AUTOSAR XML (schema 4-2-1)
package /RootP_ASWC_A7D3
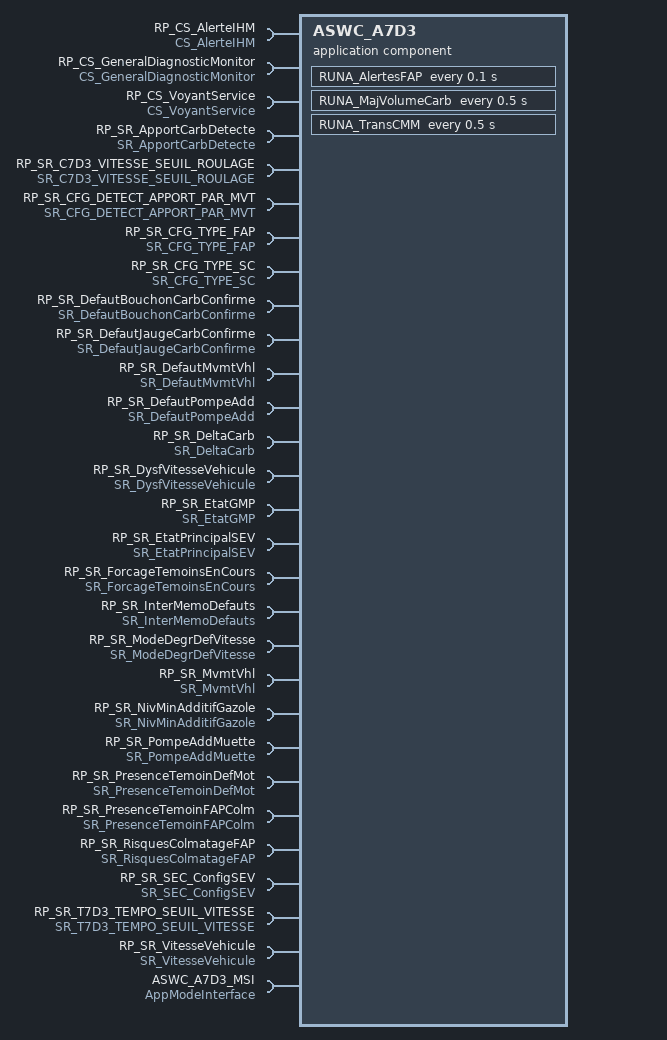
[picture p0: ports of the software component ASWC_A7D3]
  application sw component type ASWC_A7D3
    11 x provide/require port:
      PRP_SR_ContexteDefCalcAdditif: nonqueued-receiver-com-spec{data-element=ContexteDefCalcAdditif, enable-update=0, handle-data-status=1, handle-never-received=0, init-value=CONST_tLOG_0:0}, provided-required-interface=SR_ContexteDefCalcAdditif
      PRP_SR_ContexteDefCapteurBouchon: nonqueued-receiver-com-spec{data-element=ContexteDefCapteurBouchon, enable-update=0, handle-data-status=1, handle-never-received=0, init-value=CONST_tLOG_0:0}, provided-required-interface=SR_ContexteDefCapteurBouchon
      PRP_SR_ContexteDefInjecteur: nonqueued-receiver-com-spec{data-element=ContexteDefInjecteur, enable-update=0, handle-data-status=1, handle-never-received=0, init-value=CONST_tLOG_0:0}, provided-required-interface=SR_ContexteDefInjecteur
      PRP_SR_ContexteDefJaugeAdditif: nonqueued-receiver-com-spec{data-element=ContexteDefJaugeAdditif, enable-update=0, handle-data-status=1, handle-never-received=0, init-value=CONST_tLOG_0:0}, provided-required-interface=SR_ContexteDefJaugeAdditif
      PRP_SR_ContexteDefJaugeCarb: nonqueued-receiver-com-spec{data-element=ContexteDefJaugeCarb, enable-update=0, handle-data-status=1, handle-never-received=0, init-value=CONST_tLOG_0:0}, provided-required-interface=SR_ContexteDefJaugeCarb
      PRP_SR_ContexteDefPompe: nonqueued-receiver-com-spec{data-element=ContexteDefPompe, enable-update=0, handle-data-status=1, handle-never-received=0, init-value=CONST_tLOG_0:0}, provided-required-interface=SR_ContexteDefPompe
      PRP_SR_ContexteDefSondeTemp: nonqueued-receiver-com-spec{data-element=ContexteDefSondeTemp, enable-update=0, handle-data-status=1, handle-never-received=0, init-value=CONST_tLOG_0:0}, provided-required-interface=SR_ContexteDefSondeTemp
      PRP_SR_ContexteEtatAdditivation: nonqueued-receiver-com-spec{data-element=ContexteEtatAdditivation, enable-update=0, handle-data-status=1, handle-never-received=0, init-value=CONST_tLOG_1:1}, provided-required-interface=SR_ContexteEtatAdditivation
      PRP_SR_SAV_CompteurEnvoiDeltaCarb: nonqueued-receiver-com-spec{data-element=SAV_CompteurEnvoiDeltaCarb, enable-update=0, handle-data-status=1, handle-never-received=0, init-value=CONST_tBYTE_0:0}, provided-required-interface=SR_SAV_CompteurEnvoiDeltaCarb
      PRP_SR_SAV_VolCarbAjoute: nonqueued-receiver-com-spec{data-element=SAV_VolCarbAjoute, enable-update=0, handle-data-status=1, handle-never-received=0, init-value=CONST_tBYTE_0xFE:254}, provided-required-interface=SR_SAV_VolCarbAjoute
      PRP_SR_VoyRisqueColmatageFAP: nonqueued-receiver-com-spec{data-element=VoyRisqueColmatageFAP, enable-update=0, handle-data-status=1, handle-never-received=0, init-value=CONST_tLOG_0:0}, provided-required-interface=SR_VoyRisqueColmatageFAP
    29 x require port:
      RP_CS_AlerteIHM: required-interface=CS_AlerteIHM
      RP_CS_GeneralDiagnosticMonitor: required-interface=CS_GeneralDiagnosticMonitor
      RP_CS_VoyantService: required-interface=CS_VoyantService
      RP_SR_ApportCarbDetecte: nonqueued-receiver-com-spec{data-element=ApportCarbDetecte, enable-update=0, handle-data-status=1, handle-never-received=0, init-value=CONST_tLOG_0:0}, required-interface=SR_ApportCarbDetecte
      RP_SR_C7D3_VITESSE_SEUIL_ROULAGE: nonqueued-receiver-com-spec{data-element=C7D3_VITESSE_SEUIL_ROULAGE, enable-update=0, handle-data-status=1, handle-never-received=0, init-value=CONST_tBYTE_3:3}, required-interface=SR_C7D3_VITESSE_SEUIL_ROULAGE
      RP_SR_CFG_DETECT_APPORT_PAR_MVT: nonqueued-receiver-com-spec{data-element=CFG_DETECT_APPORT_PAR_MVT, enable-update=0, handle-data-status=1, handle-never-received=0, init-value=CONST_tLOG_0:0}, required-interface=SR_CFG_DETECT_APPORT_PAR_MVT
      RP_SR_CFG_TYPE_FAP: nonqueued-receiver-com-spec{data-element=CFG_TYPE_FAP, enable-update=0, handle-data-status=1, handle-never-received=0, init-value=CONST_t_cFAP_0:0}, required-interface=SR_CFG_TYPE_FAP
      RP_SR_CFG_TYPE_SC: nonqueued-receiver-com-spec{data-element=CFG_TYPE_SC, enable-update=0, handle-data-status=1, handle-never-received=0, init-value=CONST_CFG_TYPE_SC_t_cTypeSC_Euro_cTypeSC_Euro6:2}, required-interface=SR_CFG_TYPE_SC
      RP_SR_DefautBouchonCarbConfirme: nonqueued-receiver-com-spec{data-element=DefautBouchonCarbConfirme, enable-update=0, handle-data-status=1, handle-never-received=0, init-value=CONST_tLOG_0:0}, required-interface=SR_DefautBouchonCarbConfirme
      RP_SR_DefautJaugeCarbConfirme: nonqueued-receiver-com-spec{data-element=DefautJaugeCarbConfirme, enable-update=0, handle-data-status=1, handle-never-received=0, init-value=CONST_DefautJaugeCarbConfirme_t_cSDF_Defaut_cSDF_DefautAbsent:105}, required-interface=SR_DefautJaugeCarbConfirme
      RP_SR_DefautMvmtVhl: nonqueued-receiver-com-spec{data-element=DefautMvmtVhl, enable-update=0, handle-data-status=1, handle-never-received=0, init-value=CONST_tLOG_0:0}, required-interface=SR_DefautMvmtVhl
      RP_SR_DefautPompeAdd: nonqueued-receiver-com-spec{data-element=DefautPompeAdd, enable-update=0, handle-data-status=1, handle-never-received=0, init-value=CONST_tLOG_0:0}, required-interface=SR_DefautPompeAdd
      RP_SR_DeltaCarb: nonqueued-receiver-com-spec{data-element=DeltaCarb, enable-update=0, handle-data-status=1, handle-never-received=0, init-value=CONST_tWORD_0:0}, required-interface=SR_DeltaCarb
      RP_SR_DysfVitesseVehicule: nonqueued-receiver-com-spec{data-element=DysfVitesseVehicule, enable-update=0, handle-data-status=1, handle-never-received=0, init-value=CONST_t_cVitv_0:0}, required-interface=SR_DysfVitesseVehicule
      RP_SR_EtatGMP: nonqueued-receiver-com-spec{data-element=EtatGMP, enable-update=0, handle-data-status=1, handle-never-received=0, init-value=CONST_EtatGMP_t_GM_GMP_GM_GMPCoupe:1}, required-interface=SR_EtatGMP
      RP_SR_EtatPrincipalSEV: nonqueued-receiver-com-spec{data-element=EtatPrincipalSEV, enable-update=0, handle-data-status=1, handle-never-received=0, init-value=CONST_EtatPrincipalSEV_t_SEV_SEV_Arret:105}, required-interface=SR_EtatPrincipalSEV
      RP_SR_ForcageTemoinsEnCours: nonqueued-receiver-com-spec{data-element=ForcageTemoinsEnCours, enable-update=0, handle-data-status=1, handle-never-received=0, init-value=CONST_tLOG_0:0}, required-interface=SR_ForcageTemoinsEnCours
      RP_SR_InterMemoDefauts: nonqueued-receiver-com-spec{data-element=InterMemoDefauts, enable-update=0, handle-data-status=1, handle-never-received=0, init-value=CONST_tLOG_0:0}, required-interface=SR_InterMemoDefauts
      RP_SR_ModeDegrDefVitesse: nonqueued-receiver-com-spec{data-element=ModeDegrDefVitesse, enable-update=0, handle-data-status=1, handle-never-received=0, init-value=CONST_tLOG_0:0}, required-interface=SR_ModeDegrDefVitesse
      RP_SR_MvmtVhl: nonqueued-receiver-com-spec{data-element=MvmtVhl, enable-update=0, handle-data-status=1, handle-never-received=0, init-value=CONST_tLOG_0:0}, required-interface=SR_MvmtVhl
      RP_SR_NivMinAdditifGazole: nonqueued-receiver-com-spec{data-element=NivMinAdditifGazole, enable-update=0, handle-data-status=1, handle-never-received=0, init-value=CONST_tLOG_0:0}, required-interface=SR_NivMinAdditifGazole
      RP_SR_PompeAddMuette: nonqueued-receiver-com-spec{data-element=PompeAddMuette, enable-update=0, handle-data-status=1, handle-never-received=0, init-value=CONST_tLOG_0:0}, required-interface=SR_PompeAddMuette
      RP_SR_PresenceTemoinDefMot: nonqueued-receiver-com-spec{data-element=PresenceTemoinDefMot, enable-update=0, handle-data-status=1, handle-never-received=0, init-value=CONST_tLOG_0:0}, required-interface=SR_PresenceTemoinDefMot
      RP_SR_PresenceTemoinFAPColm: nonqueued-receiver-com-spec{data-element=PresenceTemoinFAPColm, enable-update=0, handle-data-status=1, handle-never-received=0, init-value=CONST_tLOG_0:0}, required-interface=SR_PresenceTemoinFAPColm
      RP_SR_RisquesColmatageFAP: nonqueued-receiver-com-spec{data-element=RisquesColmatageFAP, enable-update=0, handle-data-status=1, handle-never-received=0, init-value=CONST_tLOG_0:0}, required-interface=SR_RisquesColmatageFAP
      RP_SR_SEC_ConfigSEV: nonqueued-receiver-com-spec{data-element=SEC_ConfigSEV, enable-update=0, handle-data-status=1, handle-never-received=0, init-value=CONST_t_cCSEV_4:4}, required-interface=SR_SEC_ConfigSEV
      RP_SR_T7D3_TEMPO_SEUIL_VITESSE: nonqueued-receiver-com-spec{data-element=T7D3_TEMPO_SEUIL_VITESSE, enable-update=0, handle-data-status=1, handle-never-received=0, init-value=CONST_tBYTE_5:5}, required-interface=SR_T7D3_TEMPO_SEUIL_VITESSE
      RP_SR_VitesseVehicule: nonqueued-receiver-com-spec{data-element=VitesseVehicule, enable-update=0, handle-data-status=1, handle-never-received=0, init-value=CONST_tWORD_0:0}, required-interface=SR_VitesseVehicule
      ASWC_A7D3_MSI: required-interface=AppModeInterface
    behavior IB_ASWC_A7D3: data-type-mapping=ApplicationModeMapping, handle-termination-and-restart=NO-SUPPORT
      ar-typed-per-instance-memorys:
        17 x data:
          PA7D3_AlerteEnCoursDefautNivMiniAddGo: type=tLOG, init-value=CONST_tLOG_0:0
          PA7D3_AlerteEnCoursRisquesColmatageFAP: type=tLOG, init-value=CONST_tLOG_0:0
          PA7D3_ApportCarbDetectePrec: type=tLOG, init-value=CONST_tLOG_0:0
          PA7D3_CptTempoAppa_DefautPompeADD: type=tWORD, init-value=CONST_tWORD_0:0
          PA7D3_CptTempoDisp_DefautPompeADD: type=tWORD, init-value=CONST_tWORD_0:0
          PA7D3_DefautMvmtVhlPrec: type=tLOG, init-value=CONST_tLOG_0:0
          PA7D3_DefautPrec_DefautPompeADD: type=tBYTE, init-value=CONST_tBYTE_0:0
          PA7D3_FiltreF3: type=tWORD, init-value=CONST_tWORD_0:0
          PA7D3_FiltreGMP: type=tBYTE, init-value=CONST_tBYTE_0:0
          PA7D3_ModeDegrDefVitessePrec: type=tLOG, init-value=CONST_tLOG_0:0
          PA7D3_NivMinAdditifGazoleFiltre: type=tLOG, init-value=CONST_tLOG_0:0
          PA7D3_OldStateDef2_DefautPompeADD: type=tBYTE, init-value=CONST_tBYTE_0:0
          PA7D3_SAV_FrontApportCarbDetecte: type=tLOG, init-value=CONST_tLOG_0:0
          PA7D3_SAV_PremierPassageRealise: type=tLOG, init-value=CONST_tLOG_0:0
          PA7D3_TempoGMPNonTournant: type=tBYTE, init-value=CONST_tBYTE_0:0
          PA7D3_TempoMouvement: type=tBYTE, init-value=CONST_tBYTE_0:0
          PA7D3_TempoVitesse: type=tBYTE, init-value=CONST_tBYTE_0:0
      timing event RUNA_AlertesFAP_Cyclic: start-on-event=RUNA_AlertesFAP, period=0.1
        disabled-mode:
          ASWC_A7D3_MSI.AppMode.APP_WAKEUP
          ASWC_A7D3_MSI.AppMode.APP_OFF
          ASWC_A7D3_MSI.AppMode.APP_SYNC_INIT
          ASWC_A7D3_MSI.AppMode.APP_CONFIG
      timing event RUNA_MajVolumeCarb_Cyclic: start-on-event=RUNA_MajVolumeCarb, period=0.5
        disabled-mode:
          ASWC_A7D3_MSI.AppMode.APP_WAKEUP
          ASWC_A7D3_MSI.AppMode.APP_OFF
          ASWC_A7D3_MSI.AppMode.APP_SYNC_INIT
          ASWC_A7D3_MSI.AppMode.APP_CONFIG
      timing event RUNA_TransCMM_Cyclic: start-on-event=RUNA_TransCMM, period=0.5
        disabled-mode:
          ASWC_A7D3_MSI.AppMode.APP_WAKEUP
          ASWC_A7D3_MSI.AppMode.APP_OFF
          ASWC_A7D3_MSI.AppMode.APP_SYNC_INIT
          ASWC_A7D3_MSI.AppMode.APP_CONFIG
      runnable RUNA_AlertesFAP
        data-read-access:
          11 x access:
            dra_RP_SR_EtatGMP_EtatGMP: accessed-variable=RP_SR_EtatGMP.EtatGMP
            dra_RP_SR_EtatPrincipalSEV_EtatPrincipalSEV: accessed-variable=RP_SR_EtatPrincipalSEV.EtatPrincipalSEV
            dra_RP_SR_ForcageTemoinsEnCours_ForcageTemoinsEnCours: accessed-variable=RP_SR_ForcageTemoinsEnCours.ForcageTemoinsEnCours
            dra_RP_SR_NivMinAdditifGazole_NivMinAdditifGazole: accessed-variable=RP_SR_NivMinAdditifGazole.NivMinAdditifGazole
            dra_RP_SR_PresenceTemoinDefMot_PresenceTemoinDefMot: accessed-variable=RP_SR_PresenceTemoinDefMot.PresenceTemoinDefMot
            dra_RP_SR_PresenceTemoinFAPColm_PresenceTemoinFAPColm: accessed-variable=RP_SR_PresenceTemoinFAPColm.PresenceTemoinFAPColm
            dra_RP_SR_RisquesColmatageFAP_RisquesColmatageFAP: accessed-variable=RP_SR_RisquesColmatageFAP.RisquesColmatageFAP
            dra_RP_SR_SEC_ConfigSEV_SEC_ConfigSEV: accessed-variable=RP_SR_SEC_ConfigSEV.SEC_ConfigSEV
            dra_RP_SR_CFG_TYPE_FAP_CFG_TYPE_FAP: accessed-variable=RP_SR_CFG_TYPE_FAP.CFG_TYPE_FAP
            dra_RP_SR_CFG_TYPE_SC_CFG_TYPE_SC: accessed-variable=RP_SR_CFG_TYPE_SC.CFG_TYPE_SC
            dra_PRP_SR_VoyRisqueColmatageFAP_VoyRisqueColmatageFAP: accessed-variable=PRP_SR_VoyRisqueColmatageFAP.VoyRisqueColmatageFAP
        data-write-access:
          access dwa_PRP_SR_VoyRisqueColmatageFAP_VoyRisqueColmatageFAP: accessed-variable=PRP_SR_VoyRisqueColmatageFAP.VoyRisqueColmatageFAP
        sync call sscp_RUNA_AlertesFAP_CS_AlerteIHM_Cmd: operation=RP_CS_AlerteIHM.Cmd, timeout=0
        sync call sscp_RUNA_AlertesFAP_CS_VoyantService_Piloter: operation=RP_CS_VoyantService.Piloter, timeout=0
      runnable RUNA_MajVolumeCarb
        data-read-access:
          17 x access:
            dra_RP_SR_ApportCarbDetecte_ApportCarbDetecte: accessed-variable=RP_SR_ApportCarbDetecte.ApportCarbDetecte
            dra_RP_SR_DefautJaugeCarbConfirme_DefautJaugeCarbConfirme: accessed-variable=RP_SR_DefautJaugeCarbConfirme.DefautJaugeCarbConfirme
            dra_RP_SR_DefautMvmtVhl_DefautMvmtVhl: accessed-variable=RP_SR_DefautMvmtVhl.DefautMvmtVhl
            dra_RP_SR_DefautPompeAdd_DefautPompeAdd: accessed-variable=RP_SR_DefautPompeAdd.DefautPompeAdd
            dra_RP_SR_DeltaCarb_DeltaCarb: accessed-variable=RP_SR_DeltaCarb.DeltaCarb
            dra_RP_SR_DysfVitesseVehicule_DysfVitesseVehicule: accessed-variable=RP_SR_DysfVitesseVehicule.DysfVitesseVehicule
            dra_RP_SR_EtatGMP_EtatGMP: accessed-variable=RP_SR_EtatGMP.EtatGMP
            dra_RP_SR_InterMemoDefauts_InterMemoDefauts: accessed-variable=RP_SR_InterMemoDefauts.InterMemoDefauts
            dra_RP_SR_ModeDegrDefVitesse_ModeDegrDefVitesse: accessed-variable=RP_SR_ModeDegrDefVitesse.ModeDegrDefVitesse
            dra_RP_SR_MvmtVhl_MvmtVhl: accessed-variable=RP_SR_MvmtVhl.MvmtVhl
            dra_RP_SR_VitesseVehicule_VitesseVehicule: accessed-variable=RP_SR_VitesseVehicule.VitesseVehicule
            dra_RP_SR_C7D3_VITESSE_SEUIL_ROULAGE_C7D3_VITESSE_SEUIL_ROULAGE: accessed-variable=RP_SR_C7D3_VITESSE_SEUIL_ROULAGE.C7D3_VITESSE_SEUIL_ROULAGE
            dra_RP_SR_CFG_DETECT_APPORT_PAR_MVT_CFG_DETECT_APPORT_PAR_MVT: accessed-variable=RP_SR_CFG_DETECT_APPORT_PAR_MVT.CFG_DETECT_APPORT_PAR_MVT
            dra_RP_SR_CFG_TYPE_FAP_CFG_TYPE_FAP: accessed-variable=RP_SR_CFG_TYPE_FAP.CFG_TYPE_FAP
            dra_RP_SR_T7D3_TEMPO_SEUIL_VITESSE_T7D3_TEMPO_SEUIL_VITESSE: accessed-variable=RP_SR_T7D3_TEMPO_SEUIL_VITESSE.T7D3_TEMPO_SEUIL_VITESSE
            dra_PRP_SR_SAV_CompteurEnvoiDeltaCarb_SAV_CompteurEnvoiDeltaCarb: accessed-variable=PRP_SR_SAV_CompteurEnvoiDeltaCarb.SAV_CompteurEnvoiDeltaCarb
            dra_PRP_SR_SAV_VolCarbAjoute_SAV_VolCarbAjoute: accessed-variable=PRP_SR_SAV_VolCarbAjoute.SAV_VolCarbAjoute
        data-write-access:
          access dwa_PRP_SR_SAV_CompteurEnvoiDeltaCarb_SAV_CompteurEnvoiDeltaCarb: accessed-variable=PRP_SR_SAV_CompteurEnvoiDeltaCarb.SAV_CompteurEnvoiDeltaCarb
          access dwa_PRP_SR_SAV_VolCarbAjoute_SAV_VolCarbAjoute: accessed-variable=PRP_SR_SAV_VolCarbAjoute.SAV_VolCarbAjoute
        sync call sscp_RUNA_MajVolumeCarb_CS_GeneralDiagnosticMonitor_SetEventStatus: operation=RP_CS_GeneralDiagnosticMonitor.SetEventStatus, timeout=0
      runnable RUNA_TransCMM
        data-read-access:
          20 x access:
            dra_RP_SR_ApportCarbDetecte_ApportCarbDetecte: accessed-variable=RP_SR_ApportCarbDetecte.ApportCarbDetecte
            dra_RP_SR_DefautBouchonCarbConfirme_DefautBouchonCarbConfirme: accessed-variable=RP_SR_DefautBouchonCarbConfirme.DefautBouchonCarbConfirme
            dra_RP_SR_DefautJaugeCarbConfirme_DefautJaugeCarbConfirme: accessed-variable=RP_SR_DefautJaugeCarbConfirme.DefautJaugeCarbConfirme
            dra_RP_SR_DefautPompeAdd_DefautPompeAdd: accessed-variable=RP_SR_DefautPompeAdd.DefautPompeAdd
            dra_RP_SR_DeltaCarb_DeltaCarb: accessed-variable=RP_SR_DeltaCarb.DeltaCarb
            dra_RP_SR_DysfVitesseVehicule_DysfVitesseVehicule: accessed-variable=RP_SR_DysfVitesseVehicule.DysfVitesseVehicule
            dra_RP_SR_EtatGMP_EtatGMP: accessed-variable=RP_SR_EtatGMP.EtatGMP
            dra_RP_SR_EtatPrincipalSEV_EtatPrincipalSEV: accessed-variable=RP_SR_EtatPrincipalSEV.EtatPrincipalSEV
            dra_RP_SR_ModeDegrDefVitesse_ModeDegrDefVitesse: accessed-variable=RP_SR_ModeDegrDefVitesse.ModeDegrDefVitesse
            dra_RP_SR_PompeAddMuette_PompeAddMuette: accessed-variable=RP_SR_PompeAddMuette.PompeAddMuette
            dra_RP_SR_VitesseVehicule_VitesseVehicule: accessed-variable=RP_SR_VitesseVehicule.VitesseVehicule
            dra_RP_SR_CFG_TYPE_FAP_CFG_TYPE_FAP: accessed-variable=RP_SR_CFG_TYPE_FAP.CFG_TYPE_FAP
            dra_PRP_SR_ContexteDefCalcAdditif_ContexteDefCalcAdditif: accessed-variable=PRP_SR_ContexteDefCalcAdditif.ContexteDefCalcAdditif
            dra_PRP_SR_ContexteDefCapteurBouchon_ContexteDefCapteurBouchon: accessed-variable=PRP_SR_ContexteDefCapteurBouchon.ContexteDefCapteurBouchon
            dra_PRP_SR_ContexteDefInjecteur_ContexteDefInjecteur: accessed-variable=PRP_SR_ContexteDefInjecteur.ContexteDefInjecteur
            dra_PRP_SR_ContexteDefJaugeAdditif_ContexteDefJaugeAdditif: accessed-variable=PRP_SR_ContexteDefJaugeAdditif.ContexteDefJaugeAdditif
            dra_PRP_SR_ContexteDefJaugeCarb_ContexteDefJaugeCarb: accessed-variable=PRP_SR_ContexteDefJaugeCarb.ContexteDefJaugeCarb
            dra_PRP_SR_ContexteDefPompe_ContexteDefPompe: accessed-variable=PRP_SR_ContexteDefPompe.ContexteDefPompe
            dra_PRP_SR_ContexteDefSondeTemp_ContexteDefSondeTemp: accessed-variable=PRP_SR_ContexteDefSondeTemp.ContexteDefSondeTemp
            dra_PRP_SR_ContexteEtatAdditivation_ContexteEtatAdditivation: accessed-variable=PRP_SR_ContexteEtatAdditivation.ContexteEtatAdditivation
        data-write-access:
          8 x access:
            dwa_PRP_SR_ContexteDefCalcAdditif_ContexteDefCalcAdditif: accessed-variable=PRP_SR_ContexteDefCalcAdditif.ContexteDefCalcAdditif
            dwa_PRP_SR_ContexteDefCapteurBouchon_ContexteDefCapteurBouchon: accessed-variable=PRP_SR_ContexteDefCapteurBouchon.ContexteDefCapteurBouchon
            dwa_PRP_SR_ContexteDefInjecteur_ContexteDefInjecteur: accessed-variable=PRP_SR_ContexteDefInjecteur.ContexteDefInjecteur
            dwa_PRP_SR_ContexteDefJaugeAdditif_ContexteDefJaugeAdditif: accessed-variable=PRP_SR_ContexteDefJaugeAdditif.ContexteDefJaugeAdditif
            dwa_PRP_SR_ContexteDefJaugeCarb_ContexteDefJaugeCarb: accessed-variable=PRP_SR_ContexteDefJaugeCarb.ContexteDefJaugeCarb
            dwa_PRP_SR_ContexteDefPompe_ContexteDefPompe: accessed-variable=PRP_SR_ContexteDefPompe.ContexteDefPompe
            dwa_PRP_SR_ContexteDefSondeTemp_ContexteDefSondeTemp: accessed-variable=PRP_SR_ContexteDefSondeTemp.ContexteDefSondeTemp
            dwa_PRP_SR_ContexteEtatAdditivation_ContexteEtatAdditivation: accessed-variable=PRP_SR_ContexteEtatAdditivation.ContexteEtatAdditivation
package /RootP_Implementatation
  swc implementation Implementatation_ASWC_A7D3: programming-language=C, sw-version=1.0.0, vendor-id=1, behavior=IB_ASWC_A7D3
    code-descriptors:
      code SRC: artifact-descriptors=autosar-engineering-object={short-label=EngObject, category=SWSRC}
    resource consumption Resources
